# 3065HRPICZ register map
File version: 1.0
Registers are 32-bit, access per field, reset 0x0 unless marked. A register's access mark holds for its fields unless they carry their own. Offsets are from the block's base; [hi:lo] are bit positions.

## DAC0 — 数模转换器
Base 0x18300000
Same registers: DAC1 0x18301000, DAC2 0x18302000
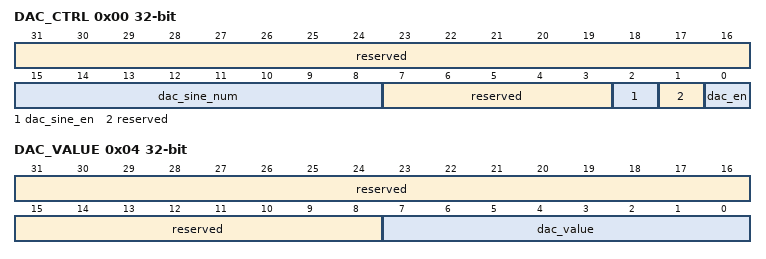
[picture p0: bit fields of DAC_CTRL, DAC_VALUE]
0x00 DAC_CTRL — DAC控制寄存器
  [31:16] reserved ro — 保留。
  [15:8] dac_sine_num rw — DAC 正弦波间隔计数值（时钟 10M 时，输出 0.3Msps 正弦波，配置为 0x21）。
  [7:3] reserved ro — 保留。
  [2] dac_sine_en rw — DAC 正弦波模式使能。0：不使能；1：使能。
  [1] reserved ro — 保留。
  [0] dac_en rw — DAC 使能。0：不使能；1：使能。
0x04 DAC_VALUE — 配置值寄存器
  [31:8] reserved ro — 保留。
  [7:0] dac_value rw — DAC 数字信号，对应电压 V=(dac_value*(VDDA−VSSA)) / 256。

## FLASH_EX — HIEFC_T40SST_REGS peripheral interface
Base 0x14710800
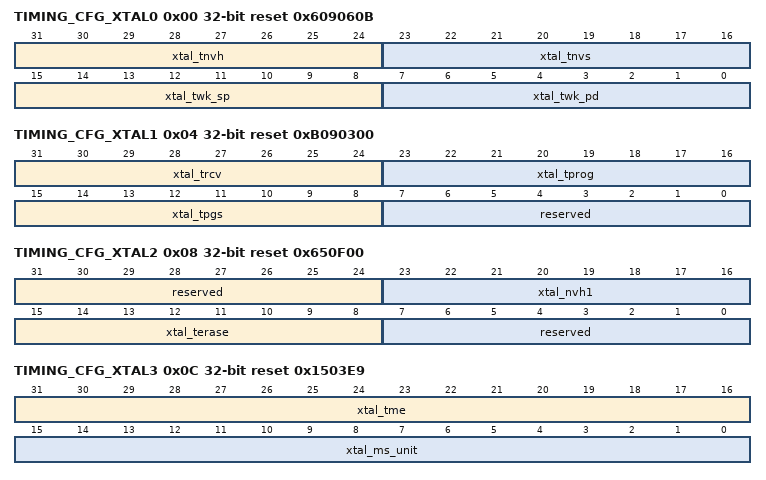
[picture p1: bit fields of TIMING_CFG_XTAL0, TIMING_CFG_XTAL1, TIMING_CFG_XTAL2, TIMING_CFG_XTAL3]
0x00 TIMING_CFG_XTAL0 rw reset 0x609060B — 晶振计数Timing Count配置寄存器0。
  [31:24] xtal_tnvh — Tnvh时序控制寄存器，Unit:1us。
  [23:16] xtal_tnvs — Tnvs时序控制寄存器，Unit:1us。
  [15:8] xtal_twk_sp — sleep到standby的唤醒时间控制寄存器，unit:1us。
  [7:0] xtal_twk_pd — power-down到standby的唤醒时间控制寄存器unit:1us。
0x04 TIMING_CFG_XTAL1 reset 0xB090300 — 晶振计数Timing Count配置寄存器1。
  [31:24] xtal_trcv rw — Trcv时序控制寄存器，Unit:1us。
  [23:16] xtal_tprog rw — Tprog时序控制寄存器，Unit:1us。
  [15:8] xtal_tpgs rw — Tpgs时序控制寄存器，Unit:1us。
  [7:0] reserved ro — 保留。
0x08 TIMING_CFG_XTAL2 reset 0x650F00 — 晶振计数Timing Count配置寄存器2。
  [31:24] reserved ro — 保留。
  [23:16] xtal_nvh1 rw — Tnvh1时序控制寄存器，Unit:1us。
  [15:8] xtal_terase rw — Terase时序控制寄存器，Unit:1ms。
  [7:0] reserved ro — 保留。
0x0C TIMING_CFG_XTAL3 rw reset 0x1503E9 — 晶振计数Timing Count配置寄存器3。
  [31:16] xtal_tme — Tme时序控制寄存器，Unit:1ms。
  [15:0] xtal_ms_unit — 1ms计时单位基准控制寄存器，Unit:1us。
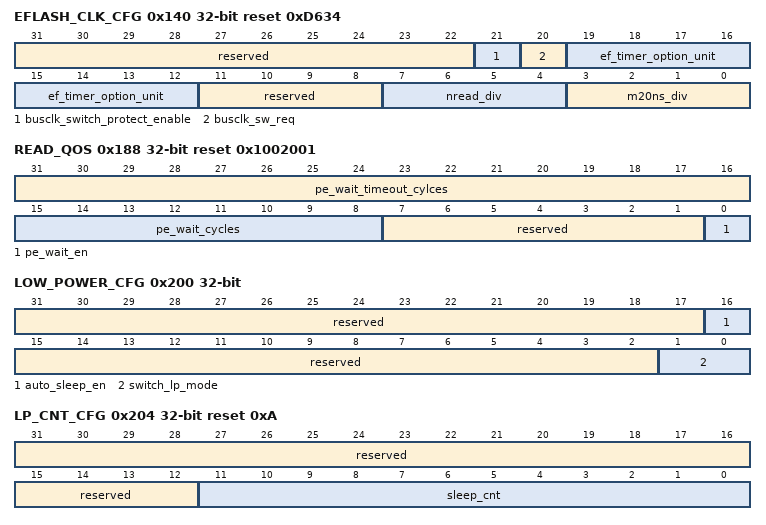
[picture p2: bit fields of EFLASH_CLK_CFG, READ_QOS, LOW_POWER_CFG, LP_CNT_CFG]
0x140 EFLASH_CLK_CFG reset 0xD634 — 时钟分频寄存器。
  [31:22] reserved ro — 保留。
  [21] busclk_switch_protect_enable rw — 切频过程保护（经中间IDLE状态下完成切频）。 0:不使能，eflash 内部分频直接切换，要求sread_div nread_div切换时，无eflash read pgm erase操作； 1:使能，crg系统时钟切换交互流程必须使能，否则 sread_div nread_div 无法切换。
  [20] busclk_sw_req rw — nread_div是否切换完成配置查询寄存器。 写1后，读回1:nread_div切换未完成，读回0:nread_div切换完成。
  [19:12] ef_timer_option_unit rw — Used to setup timer option for eflash program/erase, define numbers of clocks to generate a greater than or equal to 1us pulse, Min: 10 when clock runs at 100ns cycle。 Suggestion: pclk(MHz) Value 10 : 10 10-11 : 11 11-12 : 12 ... 97-98 : 98 98-99 : 99 99-100 : 100 default pclk 12.5MHz。
  [11:8] reserved ro — 保留。
  [7:4] nread_div rw — eflash normal read，系统总线主时钟hclk与eflash时钟比值（n+1）。要求分频后时钟小于等于50MHz 0x0: 1分频 0x1: 2分频 …… 0xf: 16分频。
  [3:0] m20ns_div rw — 内部周期不小于20ns的基准时钟，系统总线主时钟hclk与m20ns时钟比值（n+1）。 0x0: 1分频 0x1: 2分频 …… 0xf: 16分频。
0x188 READ_QOS reset 0x1002001 — 读QOS配置寄存器。
  [31:16] pe_wait_timeout_cylces rw — pe_wait使能后，pe请求被阻塞cycle超过pe_wait_timeout_cylces+pe_wait_cycles，提高pe请求优先级，优先响应pe请求。
  [15:8] pe_wait_cycles rw — 为避免稀疏的AHB读操作被PE操作阻塞，在完成AHB读操作后维持pe_wait_cycle个cycle（总线时钟），在此期间阻塞PE请求。 0表示不阻塞。
  [7:1] reserved ro — 保留。
  [0] pe_wait_en rw — PE_wait功能使能。 0:不使能 1:使能，ahb read结束后，在pe_wait_cycle时间内，阻塞pe请求，在此cycle内入股有新的ahb read请求，会优先响应ahb read。
0x200 LOW_POWER_CFG — 低功耗控制寄存器。
  [31:17] reserved ro — 保留。
  [16] auto_sleep_en rw — 自动低功耗进入Sleep控制使能。 0:不使能； 1:使能。
  [15:2] reserved ro — 保留。
  [1:0] switch_lp_mode rw — 软件直接控制低功耗切换 00:No Operation 01:Active 10:Sleep 软件写入非0值，触发状态跳转，跳转完成后自动回“00”。auto_sleep_en为0时，软件写入非0值有效，否则配置无效。
0x204 LP_CNT_CFG reset 0xA — 低功耗计数控制寄存器。
  [31:12] reserved ro — 保留。
  [11:0] sleep_cnt rw — auto sleep IDLE等待时间Unit 1us 默认:10us。 注意:配置为0时表示1us。 1us精度通过pclk计数ef_timer_option_unit个周期实现。
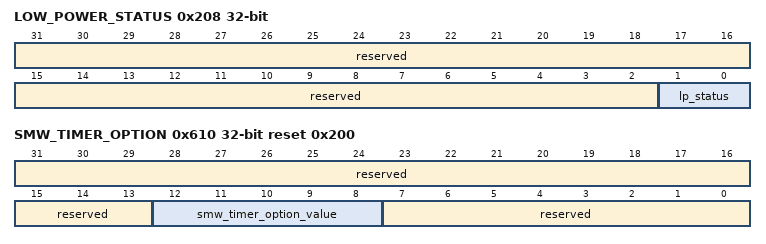
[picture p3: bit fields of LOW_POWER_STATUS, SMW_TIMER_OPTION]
0x208 LOW_POWER_STATUS ro — 低功耗状态寄存器。
  [31:2] reserved — 保留。
  [1:0] lp_status — 功耗状态机查询寄存器 00: Active state； 01: Initialization state； 10: Sleep state； 11: Power_off state。
0x610 SMW_TIMER_OPTION reset 0x200 — Smart Write timer 控制寄存器。
  [31:13] reserved ro — 保留。
  [12:8] smw_timer_option_value rw — [12:8]: define # of state required for PV/EV read cycle. The total clocks for a PV/EV read cycle will be (clock_cycle)*(setting) greater than Tmacc, and (clock_cycle)*(setting+1) greater than Tmpws (clock_cycle)*(setting+1) greater than Tmnws (clock_cycle)*2*(setting+1) greater than Tmcyc
  [7:0] reserved ro — 保留。
